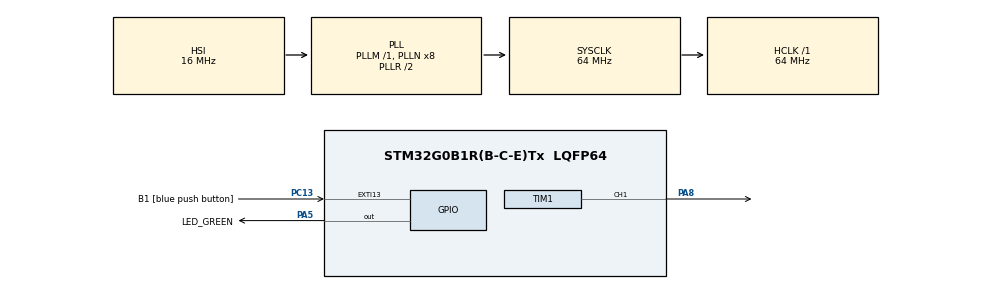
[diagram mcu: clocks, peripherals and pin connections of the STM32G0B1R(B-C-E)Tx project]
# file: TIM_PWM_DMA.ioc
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Dma.Request0=TIM1_CH1
Dma.TIM1_CH1.0.Direction=DMA_MEMORY_TO_PERIPH
Dma.TIM1_CH1.0.EventEnable=DISABLE
Dma.TIM1_CH1.0.Instance=DMA1_Channel1
Dma.TIM1_CH1.0.MemDataAlignment=DMA_MDATAALIGN_WORD
Dma.TIM1_CH1.0.MemInc=DMA_MINC_ENABLE
Dma.TIM1_CH1.0.Mode=DMA_NORMAL
Dma.TIM1_CH1.0.PeriphDataAlignment=DMA_PDATAALIGN_WORD
Dma.TIM1_CH1.0.PeriphInc=DMA_PINC_DISABLE
Dma.TIM1_CH1.0.Polarity=HAL_DMAMUX_REQ_GEN_RISING
Dma.TIM1_CH1.0.Priority=DMA_PRIORITY_LOW
Dma.TIM1_CH1.0.RequestNumber=1
Dma.TIM1_CH1.0.SignalID=NONE
Dma.TIM1_CH1.0.SyncEnable=DISABLE
Dma.TIM1_CH1.0.SyncPolarity=HAL_DMAMUX_SYNC_NO_EVENT
Dma.TIM1_CH1.0.SyncRequestNumber=1
Dma.TIM1_CH1.0.SyncSignalID=NONE
Mcu.Family=STM32G0
Mcu.Name=STM32G0B1R(B-C-E)Tx
Mcu.Package=LQFP64
NVIC.DMA1_Channel1_IRQn=true\:0\:0\:false\:false\:true\:false\:true\:true
PA13.GPIO_Label=TMS
PA13.Signal=SYS_SWDIO
PA14-BOOT0.GPIO_Label=TCK
PA14-BOOT0.Signal=SYS_SWCLK
PA2.GPIO_Label=USART2_TX [STLK_TX]
PA2.Signal=USART2_TX
PA3.GPIO_Label=USART2_RX [STLK_RX]
PA3.Signal=USART2_RX
PA5.GPIO_Label=LED_GREEN
PA5.GPIO_Speed=GPIO_SPEED_FREQ_HIGH
PA5.Signal=GPIO_Output
PA8.Signal=S_TIM1_CH1
PC13.GPIO_Label=B1 [blue push button]
PC13.Signal=GPXTI13
PC14-OSC32_IN\ (PC14).Signal=RCC_OSC32_IN
PC15-OSC32_OUT\ (PC15).Signal=RCC_OSC32_OUT
PF0-OSC_IN\ (PF0).GPIO_Label=MCO
PF0-OSC_IN\ (PF0).Signal=RCC_OSC_IN
ProjectManager.HeapSize=0x200
ProjectManager.StackSize=0x400
ProjectManager.TargetToolchain=STM32CubeIDE
RCC.ADCFreq_Value=64000000
RCC.AHBFreq_Value=64000000
RCC.CortexFreq_Value=64000000
RCC.EXTERNAL_CLOCK_VALUE=12288000
RCC.HCLKFreq_Value=64000000
RCC.HSE_VALUE=8000000
RCC.HSI48_VALUE=48000000
RCC.HSI_VALUE=16000000
RCC.LSE_VALUE=32768
RCC.SYSCLKFreq_VALUE=64000000
RCC.SYSCLKSource=RCC_SYSCLKSOURCE_PLLCLK
RCC.USBFreq_Value=48000000
RCC.VCOOutputFreq_Value=128000000
SH.S_TIM1_CH1.0=TIM1_CH1,PWM Generation1 CH1
TIM1.Channel-PWM\ Generation1\ CH1=TIM_CHANNEL_1
TIM1.CounterMode=TIM_COUNTERMODE_UP
TIM1.Period=6400
TIM1.Prescaler=0
TIM1.Pulse-PWM\ Generation1\ CH1=3200
VP_SYS_VS_DBSignals.Mode=DisableDeadBatterySignals
VP_TIM1_VS_ClockSourceINT.Mode=Internal
board=NUCLEO-G0B1RE

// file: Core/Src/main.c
/* USER CODE BEGIN Header */
/**
  ******************************************************************************
  * @file           : main.c
  * @brief          : Main program body
  ******************************************************************************
  * @attention
  *
  * Copyright (c) 2025 STMicroelectronics.
  * All rights reserved.
  *
  * This software is licensed under terms that can be found in the LICENSE file
  * in the root directory of this software component.
  * If no LICENSE file comes with this software, it is provided AS-IS.
  *
  ******************************************************************************
  */
/* USER CODE END Header */
#include "main.h"

TIM_HandleTypeDef htim1;
DMA_HandleTypeDef hdma_tim1_ch1;

void SystemClock_Config(void);
static void MX_GPIO_Init(void);
static void MX_DMA_Init(void);
static void MX_TIM1_Init(void);

int main(void)
{

  /* MCU Configuration--------------------------------------------------------*/

  /* Reset of all peripherals, Initializes the Flash interface and the Systick. */
  HAL_Init();

  /* Configure the system clock */
  SystemClock_Config();

  /* Initialize all configured peripherals */
  MX_GPIO_Init();
  MX_DMA_Init();
  MX_TIM1_Init();
  /* USER CODE BEGIN 2 */
  uint32_t pwmDutyCycleBuffer[5];

  	 // Fill the buffer with duty cycle values (0 to 100%)
  	    for (int i = 0; i < 5; i++) {
  	        pwmDutyCycleBuffer[i] = i * (htim1.Init.Period + 1) / 10;
  	    }

  	    // Start PWM with DMA
  	    HAL_TIM_PWM_Start(&htim1, TIM_CHANNEL_1);
  	    HAL_DMA_Start(&hdma_tim1_ch1, (uint32_t)pwmDutyCycleBuffer, (uint32_t)&htim1.Instance->CCR1, 5);
  	    __HAL_TIM_ENABLE_DMA(&htim1, TIM_DMA_CC1);

  /* USER CODE END 2 */

  /* Infinite loop */
  while (1)
  {

  }
}

void SystemClock_Config(void)
{
  RCC_OscInitTypeDef RCC_OscInitStruct = {0};
  RCC_ClkInitTypeDef RCC_ClkInitStruct = {0};

  /** Configure the main internal regulator output voltage
  */
  HAL_PWREx_ControlVoltageScaling(PWR_REGULATOR_VOLTAGE_SCALE1);

  /** Initializes the RCC Oscillators according to the specified parameters
  * in the RCC_OscInitTypeDef structure.
  */
  RCC_OscInitStruct.OscillatorType = RCC_OSCILLATORTYPE_HSI;
  RCC_OscInitStruct.HSIState = RCC_HSI_ON;
  RCC_OscInitStruct.HSIDiv = RCC_HSI_DIV1;
  RCC_OscInitStruct.HSICalibrationValue = RCC_HSICALIBRATION_DEFAULT;
  RCC_OscInitStruct.PLL.PLLState = RCC_PLL_ON;
  RCC_OscInitStruct.PLL.PLLSource = RCC_PLLSOURCE_HSI;
  RCC_OscInitStruct.PLL.PLLM = RCC_PLLM_DIV1;
  RCC_OscInitStruct.PLL.PLLN = 8;
  RCC_OscInitStruct.PLL.PLLP = RCC_PLLP_DIV2;
  RCC_OscInitStruct.PLL.PLLQ = RCC_PLLQ_DIV2;
  RCC_OscInitStruct.PLL.PLLR = RCC_PLLR_DIV2;
  if (HAL_RCC_OscConfig(&RCC_OscInitStruct) != HAL_OK)
  {
    Error_Handler();
  }

  /** Initializes the CPU, AHB and APB buses clocks
  */
  RCC_ClkInitStruct.ClockType = RCC_CLOCKTYPE_HCLK|RCC_CLOCKTYPE_SYSCLK
                              |RCC_CLOCKTYPE_PCLK1;
  RCC_ClkInitStruct.SYSCLKSource = RCC_SYSCLKSOURCE_PLLCLK;
  RCC_ClkInitStruct.AHBCLKDivider = RCC_SYSCLK_DIV1;
  RCC_ClkInitStruct.APB1CLKDivider = RCC_HCLK_DIV1;

  if (HAL_RCC_ClockConfig(&RCC_ClkInitStruct, FLASH_LATENCY_2) != HAL_OK)
  {
    Error_Handler();
  }
}

static void MX_TIM1_Init(void)
{

  TIM_ClockConfigTypeDef sClockSourceConfig = {0};
  TIM_MasterConfigTypeDef sMasterConfig = {0};
  TIM_OC_InitTypeDef sConfigOC = {0};
  TIM_BreakDeadTimeConfigTypeDef sBreakDeadTimeConfig = {0};

  htim1.Instance = TIM1;
  htim1.Init.Prescaler = 0;
  htim1.Init.CounterMode = TIM_COUNTERMODE_UP;
  htim1.Init.Period = 6400;
  htim1.Init.ClockDivision = TIM_CLOCKDIVISION_DIV1;
  htim1.Init.RepetitionCounter = 0;
  htim1.Init.AutoReloadPreload = TIM_AUTORELOAD_PRELOAD_DISABLE;
  if (HAL_TIM_Base_Init(&htim1) != HAL_OK)
  {
    Error_Handler();
  }
  sClockSourceConfig.ClockSource = TIM_CLOCKSOURCE_INTERNAL;
  if (HAL_TIM_ConfigClockSource(&htim1, &sClockSourceConfig) != HAL_OK)
  {
    Error_Handler();
  }
  if (HAL_TIM_PWM_Init(&htim1) != HAL_OK)
  {
    Error_Handler();
  }
  sMasterConfig.MasterOutputTrigger = TIM_TRGO_RESET;
  sMasterConfig.MasterOutputTrigger2 = TIM_TRGO2_RESET;
  sMasterConfig.MasterSlaveMode = TIM_MASTERSLAVEMODE_DISABLE;
  if (HAL_TIMEx_MasterConfigSynchronization(&htim1, &sMasterConfig) != HAL_OK)
  {
    Error_Handler();
  }
  sConfigOC.OCMode = TIM_OCMODE_PWM1;
  sConfigOC.Pulse = 3200;
  sConfigOC.OCPolarity = TIM_OCPOLARITY_HIGH;
  sConfigOC.OCNPolarity = TIM_OCNPOLARITY_HIGH;
  sConfigOC.OCFastMode = TIM_OCFAST_DISABLE;
  sConfigOC.OCIdleState = TIM_OCIDLESTATE_RESET;
  sConfigOC.OCNIdleState = TIM_OCNIDLESTATE_RESET;
  if (HAL_TIM_PWM_ConfigChannel(&htim1, &sConfigOC, TIM_CHANNEL_1) != HAL_OK)
  {
    Error_Handler();
  }
  sBreakDeadTimeConfig.OffStateRunMode = TIM_OSSR_DISABLE;
  sBreakDeadTimeConfig.OffStateIDLEMode = TIM_OSSI_DISABLE;
  sBreakDeadTimeConfig.LockLevel = TIM_LOCKLEVEL_OFF;
  sBreakDeadTimeConfig.DeadTime = 0;
  sBreakDeadTimeConfig.BreakState = TIM_BREAK_DISABLE;
  sBreakDeadTimeConfig.BreakPolarity = TIM_BREAKPOLARITY_HIGH;
  sBreakDeadTimeConfig.BreakFilter = 0;
  sBreakDeadTimeConfig.BreakAFMode = TIM_BREAK_AFMODE_INPUT;
  sBreakDeadTimeConfig.Break2State = TIM_BREAK2_DISABLE;
  sBreakDeadTimeConfig.Break2Polarity = TIM_BREAK2POLARITY_HIGH;
  sBreakDeadTimeConfig.Break2Filter = 0;
  sBreakDeadTimeConfig.Break2AFMode = TIM_BREAK_AFMODE_INPUT;
  sBreakDeadTimeConfig.AutomaticOutput = TIM_AUTOMATICOUTPUT_DISABLE;
  if (HAL_TIMEx_ConfigBreakDeadTime(&htim1, &sBreakDeadTimeConfig) != HAL_OK)
  {
    Error_Handler();
  }
  HAL_TIM_MspPostInit(&htim1);

}

static void MX_DMA_Init(void)
{

  /* DMA controller clock enable */
  __HAL_RCC_DMA1_CLK_ENABLE();

  /* DMA interrupt init */
  /* DMA1_Channel1_IRQn interrupt configuration */
  HAL_NVIC_SetPriority(DMA1_Channel1_IRQn, 0, 0);
  HAL_NVIC_EnableIRQ(DMA1_Channel1_IRQn);

}

static void MX_GPIO_Init(void)
{
  GPIO_InitTypeDef GPIO_InitStruct = {0};

  /* GPIO Ports Clock Enable */
  __HAL_RCC_GPIOC_CLK_ENABLE();
  __HAL_RCC_GPIOF_CLK_ENABLE();
  __HAL_RCC_GPIOA_CLK_ENABLE();

  /*Configure GPIO pin Output Level */
  HAL_GPIO_WritePin(LED_GREEN_GPIO_Port, LED_GREEN_Pin, GPIO_PIN_RESET);

  /*Configure GPIO pin : B1_Pin */
  GPIO_InitStruct.Pin = B1_Pin;
  GPIO_InitStruct.Mode = GPIO_MODE_IT_RISING;
  GPIO_InitStruct.Pull = GPIO_NOPULL;
  HAL_GPIO_Init(B1_GPIO_Port, &GPIO_InitStruct);

  /*Configure GPIO pins : USART2_TX_Pin USART2_RX_Pin */
  GPIO_InitStruct.Pin = USART2_TX_Pin|USART2_RX_Pin;
  GPIO_InitStruct.Mode = GPIO_MODE_AF_PP;
  GPIO_InitStruct.Pull = GPIO_NOPULL;
  GPIO_InitStruct.Speed = GPIO_SPEED_FREQ_LOW;
  GPIO_InitStruct.Alternate = GPIO_AF1_USART2;
  HAL_GPIO_Init(GPIOA, &GPIO_InitStruct);

  /*Configure GPIO pin : LED_GREEN_Pin */
  GPIO_InitStruct.Pin = LED_GREEN_Pin;
  GPIO_InitStruct.Mode = GPIO_MODE_OUTPUT_PP;
  GPIO_InitStruct.Pull = GPIO_NOPULL;
  GPIO_InitStruct.Speed = GPIO_SPEED_FREQ_HIGH;
  HAL_GPIO_Init(LED_GREEN_GPIO_Port, &GPIO_InitStruct);

}

void Error_Handler(void)
{
  __disable_irq();
  while (1)
  {
  }
}
